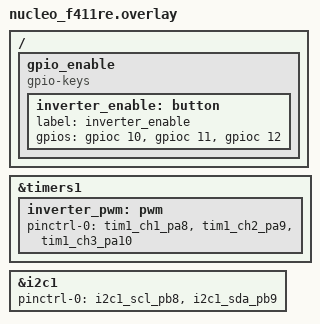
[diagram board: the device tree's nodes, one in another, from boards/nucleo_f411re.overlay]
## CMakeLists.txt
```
cmake_minimum_required(VERSION 3.13.1)
find_package(Zephyr REQUIRED HINTS $ENV{ZEPHYR_BASE})
project(step_foc)

target_sources(app PRIVATE src/foc_driver.c)
target_sources(app PRIVATE src/main.c)
target_sources(app PRIVATE src/foc_nodes.c)
```

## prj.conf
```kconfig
CONFIG_PRINTK=y
CONFIG_SERIAL=y
CONFIG_CBPRINTF_FP_SUPPORT=y

CONFIG_SHELL=y
CONFIG_SHELL_HISTORY=y
CONFIG_SHELL_VT100_COLORS=y

CONFIG_LOG=y
CONFIG_LOG_MODE_DEFERRED=y

CONFIG_STEP=y

# necessary to use CMSIS-DSP
CONFIG_NEWLIB_LIBC=y
CONFIG_CMSIS_DSP=y
CONFIG_CMSIS_DSP_FASTMATH=y
CONFIG_CMSIS_DSP_CONTROLLER=y

# enable PWM
CONFIG_PWM=y

# also the I2C:
CONFIG_I2C=y
```

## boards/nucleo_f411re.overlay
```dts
/*
 * SPDX-License-Identifier: Apache-2.0
 *
 * Copyright (c) 2022 Linaro
 */

 #include <dt-bindings/pwm/pwm.h>

/ {
	gpio_enable {
		compatible = "gpio-keys";
		inverter_enable: button {
			label = "inverter_enable";
			gpios = <&gpioc 10 GPIO_ACTIVE_HIGH>,
                    <&gpioc 11 GPIO_ACTIVE_HIGH>,
                    <&gpioc 12 GPIO_ACTIVE_HIGH>;
		};
	};
};
 
 /* Set PWM that are attached to the IHM07 dev board's power stage */
 &timers1 {
     status = "okay";
 
     inverter_pwm: pwm {
         status = "okay";
         pinctrl-0 = <&tim1_ch1_pa8 &tim1_ch2_pa9 &tim1_ch3_pa10>; 
         pinctrl-names = "default";
     };
};

&i2c1 {
	pinctrl-0 = <&i2c1_scl_pb8 &i2c1_sda_pb9>;
	pinctrl-names = "default";
	status = "okay";
};
```

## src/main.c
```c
/*
 * Copyright (c) 2022 Linaro
 *
 * SPDX-License-Identifier: Apache-2.0
 */

#include <zephyr/kernel.h>
#include <stdlib.h>
#include <step/step.h>
#include <step/proc_mgr.h>
#include <zephyr/shell/shell.h>
#include "foc_driver.h"
#include "foc_nodes.h"

#define SAMPLE_MOTOR_POLE_PAIRS 	7

static float motor_vq;
static float motor_vd;

void on_foc_measurement(struct step_measurement *mes)
{
	/* just update the desired voltage, data publish is handled by
	 * by the driver automatically
	 */
	struct foc_controller_payload *p = mes->payload;
	p->cmd.voltage_q = motor_vq;
	p->cmd.voltage_d = motor_vd;
}

void main(void)
{	
	int rc = 0;
	uint32_t handle;

	motor_vq = 0.0f;
	motor_vd = 0.0f;

	/* initialize the foc driver first */
	rc = foc_driver_initialize(SAMPLE_MOTOR_POLE_PAIRS,
							on_foc_measurement);
	if (rc) {
		printk("foc driver init failed!\n");
		return;
	}

	/* Then register the FoC processing pipeline */
	rc = step_pm_register(foc_node_chain, 0, &handle);
	if (rc) {
		printk("Node registration failed!\n");
		return;
	}
}

static int step_foc_cmd_set(const struct shell *shell, size_t argc, char **argv)
{
	if (argc != 3) {
		return -EINVAL;
	}

	motor_vq = strtof(argv[1], NULL);
	motor_vd = strtof(argv[2], NULL);
	return 0;
}

static int step_foc_cmd_align(const struct shell *shell, size_t argc, char **argv)
{
	return foc_driver_set_encoder_offset();
}

/* Subcommand array for "step_foc" (level 1). */
SHELL_STATIC_SUBCMD_SET_CREATE(
	sub_step_foc,
	SHELL_CMD(set, NULL, "Set voltage d-q vector to control the motor between -1 and +1", step_foc_cmd_set),
	SHELL_CMD(align, NULL, "Align rotor and calibrate its position sensor", step_foc_cmd_align),	
	SHELL_SUBCMD_SET_END
	);

/* Root command "step_foc" (level 0). */
SHELL_CMD_REGISTER(step_foc, &sub_step_foc, "Secure telemetry pipeline FoC sample commands", NULL);
```

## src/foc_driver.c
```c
/*
 * Copyright (c) 2022 Linaro
 *
 * SPDX-License-Identifier: Apache-2.0
 */

#include <arm_math.h>
#include <string.h>
#include <zephyr/kernel.h>
#include <zephyr/device.h>
#include <zephyr/drivers/i2c.h>
#include <zephyr/drivers/pwm.h>
#include <zephyr/drivers/gpio.h>
#include <zephyr/sys/printk.h>
#include <step/sample_pool.h>
#include <step/proc_mgr.h>
#include "foc_driver.h"

/** AS5600 I2C Encoder constants */
#define AS5600_SLAVE_ADDR 0x36
#define AS5600_ANGLE_REGISTER_H 0x0E
#define AS5600_PULSES_PER_REVOLUTION 4096.0f
#define AS5600_READING_MASK 0xFFF 

#define ROTOR_DRV_PAYLOAD_SZ      (sizeof(struct foc_controller_payload))
#define ROTOR_DRV_PAYLOAD_SRC_ID  (2)

/* PWM frequency about 16KHz */
#define PWM_PERIOD_NSEC 62500

/**
 * @brief Pre-populated measurement header to copy into allocated measurements.
 */
static struct step_mes_header rotor_sensor_header = {
	/* Filter word. */
	.filter = {
		.base_type = STEP_MES_TYPE_PHASE,
		.flags = {
			.data_format = STEP_MES_FORMAT_NONE,
			.encoding = STEP_MES_ENCODING_NONE,
			.compression = STEP_MES_COMPRESSION_NONE,
			.timestamp = STEP_MES_TIMESTAMP_UPTIME_MS_32,
		},
	},
	/* SI Unit word. */
	.unit = {
		.si_unit = STEP_MES_UNIT_SI_RADIAN,
		.ctype = STEP_MES_UNIT_CTYPE_IEEE754_FLOAT32,
		.scale_factor = STEP_MES_SI_SCALE_NONE,
	},
	/* Source/Len word. */
	.srclen = {
		.len = ROTOR_DRV_PAYLOAD_SZ,
		.fragment = 0,
		.sourceid = ROTOR_DRV_PAYLOAD_SRC_ID,
	}
};

static void foc_driver_rotor_position_sample_thread(void *arg);

/* Rotor sensor measurement thread. */
K_THREAD_DEFINE(rotor_sample_tid, 4096,
		foc_driver_rotor_position_sample_thread, NULL, NULL, NULL,
		-1, 0, 0);

const static float encoder_to_degrees_ratio = (360.0f) / AS5600_PULSES_PER_REVOLUTION;

static foc_measurement_callback_t user_callback;
static float pole_pairs;

static struct {
	uint16_t raw;
	uint16_t zero_offset;
} encoder_reading;

static const struct device *inverter_pwm = DEVICE_DT_GET(DT_NODELABEL(inverter_pwm));
static const struct device *encoder_i2c = DEVICE_DT_GET(DT_NODELABEL(i2c1));

static struct gpio_dt_spec enable_u = GPIO_DT_SPEC_GET_BY_IDX(DT_NODELABEL(inverter_enable),gpios,0);
static struct gpio_dt_spec enable_v = GPIO_DT_SPEC_GET_BY_IDX(DT_NODELABEL(inverter_enable),gpios,1);
static struct gpio_dt_spec enable_w = GPIO_DT_SPEC_GET_BY_IDX(DT_NODELABEL(inverter_enable),gpios,2);

static uint16_t foc_driver_read_encoder(void)
{
	uint16_t raw;
	uint8_t read_data[2] = {0,0};
	uint8_t angle_reg = AS5600_ANGLE_REGISTER_H;

	/* gets the raw position from encoder */
	int err = i2c_write_read(encoder_i2c, 
						AS5600_SLAVE_ADDR,
						&angle_reg,
						1,
						&read_data,
						sizeof(read_data));

	if(err) {
		return 0xFFFF;
	}

	raw = ((uint16_t)read_data[0] << 8) | read_data[1];

	/* wrap to its maximum value */
	if(raw > AS5600_PULSES_PER_REVOLUTION - 1) {
		raw = AS5600_PULSES_PER_REVOLUTION - 1 ;
	}

	return raw;
}

static void foc_driver_get_rotor_position(struct step_measurement * rotor_measurement)
{
	struct foc_controller_payload *p = rotor_measurement->payload;
	struct foc_feeback_sensor_data *fdbk = &p->state;

	fdbk->motor_pole_pairs = pole_pairs;

	/* update the encoder reading */
	encoder_reading.raw = foc_driver_read_encoder();

	/* make encoder measures to radians for mech and electrical angle */
	fdbk->rotor_position = (float)((encoder_reading.raw - encoder_reading.zero_offset) &
						 AS5600_READING_MASK) * encoder_to_degrees_ratio;
	fdbk->e_rotor_position = fdbk->motor_pole_pairs * fdbk->rotor_position;

	p->timestamp = k_uptime_get_32();
}

static void foc_driver_rotor_position_sample_thread(void *arg)
{	
	for(;;) {
		struct step_measurement *rotor_measurement =  step_sp_alloc(ROTOR_DRV_PAYLOAD_SZ);

		foc_driver_get_rotor_position(rotor_measurement);

		/* fill measurements information before publishing: */
		rotor_measurement->header.filter_bits = rotor_sensor_header.filter_bits;
		rotor_measurement->header.unit_bits = rotor_sensor_header.unit_bits;
		rotor_measurement->header.srclen_bits = rotor_sensor_header.srclen_bits;

		if(user_callback) {
			user_callback(rotor_measurement);
		}

		step_pm_put(rotor_measurement);
	}
}

int foc_driver_initialize(float motor_pole_pairs, foc_measurement_callback_t cb)
{
	int rc = 0;

	user_callback = cb;
	pole_pairs = motor_pole_pairs;

	encoder_reading.raw = 0;
	encoder_reading.zero_offset = 0;

	i2c_configure(encoder_i2c, I2C_MODE_MASTER | I2C_SPEED_FAST);
	foc_driver_set_duty_cycle(0.0f, 0.0f, 0.0f);

	gpio_pin_configure_dt(&enable_u, GPIO_OUTPUT);
	gpio_pin_configure_dt(&enable_v, GPIO_OUTPUT);
	gpio_pin_configure_dt(&enable_w, GPIO_OUTPUT);

	gpio_pin_set_dt(&enable_u, 1);
	gpio_pin_set_dt(&enable_v, 1);
	gpio_pin_set_dt(&enable_w, 1);

	return rc;
}

int foc_driver_set_encoder_offset(void)
{
	/* align rotor each startup */
	encoder_reading.zero_offset = foc_driver_read_encoder() & AS5600_READING_MASK;

	return 0;
}

void foc_driver_set_duty_cycle(float dc_u, float dc_v, float dc_w)
{
	/* saturate the duties */
	if(dc_u > 1.0f) {
		dc_u = 1.0f;
	} else if (dc_u < 0.0f) {
		dc_u = 0.0f;
	}

	if(dc_v > 1.0f) {
		dc_v = 1.0f;
	} else if (dc_v < 0.0f) {
		dc_v = 0.0f;
	}

	if(dc_w > 1.0f) {
		dc_w = 1.0f;
	} else if (dc_w < 0.0f) {
		dc_w = 0.0f;
	}

	/* scale the duty cycle to nanoseconds */
	dc_u *= PWM_PERIOD_NSEC - 1;
	dc_v *= PWM_PERIOD_NSEC - 1;
	dc_w *= PWM_PERIOD_NSEC - 1;

	pwm_set(inverter_pwm, 1 , PWM_PERIOD_NSEC, dc_u, 0);
	pwm_set(inverter_pwm, 2 , PWM_PERIOD_NSEC, dc_v, 0);
	pwm_set(inverter_pwm, 3 , PWM_PERIOD_NSEC, dc_w, 0);
}
```

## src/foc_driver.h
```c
/*
 * Copyright (c) 2022 Linaro
 *
 * SPDX-License-Identifier: Apache-2.0
 */

#ifndef FOC_DRIVER_H__
#define FOC_DRIVER_H__

#include <step/step.h>
#include <step/measurement/measurement.h>

#ifdef __cplusplus
extern "C" {
#endif

/**
 * @brief FoC measurement reception callback:
 */
typedef void (*foc_measurement_callback_t) (struct step_measurement *mes);

/**
 * @brief FoC rotor position sensor data:
 */
struct foc_feeback_sensor_data {
	float motor_pole_pairs;
	float e_rotor_position;
	float rotor_position;
};

/**
 * @brief FoC voltages flow data:
 */
struct foc_command_data {
	float voltage_q;
	float voltage_d;
	float voltage_alpha;
	float voltage_beta;
	float voltage_u;
	float voltage_v;
};

/**
 * @brief FoC data payload descriptor:
 */
struct foc_controller_payload {
	uint32_t timestamp;
	struct foc_feeback_sensor_data state;
	struct foc_command_data cmd;
};

/**
 * @brief Initializes the foc driver.
 * 
 * @param cb user callback to be executed each measurement from motor rotor position.
 * 
 * @param dc_link_voltage inverter dc bus voltage in volts.
 *
 * @param motor_pole_pairs number of motor pole pairs.
 * 
 * @return int  0 on success, otherwise a negative error code.
 * 
 */
int foc_driver_initialize(float motor_pole_pairs, float dc_link_voltage, foc_measurement_callback_t cb);


/**
 * @brief Sets the 0-degree offset for the encoder
 * 
 * @return int  0 on success, otherwise a negative error code.
 * 
 */
int foc_driver_set_encoder_offset(void);

/**
 * @brief set inverter voltages.
 * 
 * @param voltage_u voltage to be applied to the in phase u of motor
 *
 * @param voltage_v voltage to be applied to the in phase v of motor
 * 
 */
void foc_driver_set_voltages(float voltage_u, float voltage_v);

#ifdef __cplusplus
}
#endif

#endif /* STEP_SHELL_DRIVER_H_ */
```

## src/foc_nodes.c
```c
/*
 * Copyright (c) 2022 Linaro
 *
 * SPDX-License-Identifier: Apache-2.0
 */

#include <zephyr/kernel.h>
#include <stdio.h>
#include <zephyr/logging/log.h>
#include <step/proc_mgr.h>
#include "foc_nodes.h"
#include "foc_driver.h"
#include "foc_svm.h"
#include <arm_math.h>

/**
 *  ┌───────────────┐
 *  │               │
 *  │ Rotor Sensor  │          This is the FoC pipeline created using STeP:
 *  │ (I2C)         │       1. Collect node which is trigggered by rotor position sensor driver
 *  │               │       2. Inverse Park transfor to map VQD to rotating VaplhaBeta
 *  │               │       3. Inverse Clarke transform to project ValphaBeta into 3-phase vector
 *  └──────┬────────┘       4. Inverter update node that sends 3-phase vector to the PWM driver
 *         │
 *         │                The STeP node chain is created to represent the block diagram
 *         │                below.
 *         │
 *         │
 *         │           ---------------------------------------------------
 *         │		   | FoC algorithm Node								 |						 	
 * ┌───────▼────────┐  | ┌────────────────┐            ┌───────────────┐ |       ┌────────────────┐
 * │                │  | │                │            │               │ |       │                │
 * │  Collect       │  | │ Inverse        │            │ Inverse       │ |       │ Inverter       │
 * │  Node          │  | │ Park Transform │            │ Clarke Trans. │ |       │ Update         │
 * │                ├───►│                ├────────────►               ├────────►│ Node           │
 * │  Capture       │  | │ VQD -> Vab     │            │ Vab->Vuvw     │ |       │ Vuvw-> SVPWM   │
 * │  the samples   │  | │                │            │               │ |       │                │
 * │                │  | │                │            │               │ |       │                │
 * └───────▲────────┘  | └────────────────┘            └───────────────┘ |       └────────┬───────┘
 *         │           |                                                 |                │
 *         │           |-------------------------------------------------|                │
 *         │                                                                              ▼
 *         │                                                                     ┌────────────────┐
 *  ┌──────┴────────┐                                                            │                │
 *  │               │                                                            │ Inverter       │
 *  │ Desired       │                                                            │ Driver         │
 *  │ Voltage       │                                                            │                │
 *  │ (Shell)       │                                                            │ (PWM)          │
 *  │               │                                                            │                │
 *  │               │                                                            └────────────────┘
 *  └───────────────┘
 */

/* rotor sensor align step */
int foc_align_rotor(void *cfg, uint32_t handle, uint32_t inst)
{
	/* for rotor alignment the idea is to provide the initial voltage
	 * vector with a phase of 90 degree and apply to the motor, and wait
	 * the rotor to align mechanically to that voltage applied, this will
	 * translate the stator and rotor magnetic fields are properly 90 degree
	 * aligned
	 */
	float sine;
	float cosine;
	float alpha;
	float beta;
	float inverter_duties[3];

	/* we want a voltage vector with 90 degree of phase */
	arm_sin_cos_f32(90, &sine, &cosine);

	/* use only 20% of the current capacity to avoid heating*/
	arm_inv_park_f32(0.0f,
					0.1f,
					&alpha,
					&beta,
					sine,
					cosine);

	/* convert the alpha-beta frame into SVPWM signals */
	foc_svm_set(alpha, 
			beta,
			&inverter_duties[0],
			&inverter_duties[1],
			&inverter_duties[2]);

	/* set the voltage vector to the inverter and... */
	foc_driver_set_duty_cycle(inverter_duties[0], inverter_duties[1], inverter_duties[2]);
	
	/* give a delay to the rotor align mechanically */
	k_sleep(K_MSEC(500));

	/* before releasing the voltage, sets the zero angle offset in the encoder*/
	return foc_driver_set_encoder_offset();
}

/* foc algorithm process step */
int foc_do_process(struct step_measurement *mes, uint32_t handle, uint32_t inst)
{
	struct foc_controller_payload *p = mes->payload;
	struct foc_command_data *command = &p->cmd;
	struct foc_feeback_sensor_data *feed = &p->state;
	float sine;
	float cosine;

	arm_sin_cos_f32(feed->e_rotor_position, &sine, &cosine);

	arm_inv_park_f32(command->voltage_d,
					command->voltage_q,
					&command->voltage_alpha,
					&command->voltage_beta,
					sine,
					cosine);
	
	return 0;
}

/* do SVPWM update the inverter step, the last block on FoC chain */
int foc_do_space_vector_modulation(struct step_measurement *mes, uint32_t handle, uint32_t inst)
{
	struct foc_controller_payload *p = mes->payload;
	float inverter_duties[3];

	/* convert the alpha-beta frame into SVPWM signals */
	foc_svm_set(p->cmd.voltage_alpha, 
			p->cmd.voltage_beta,
			&inverter_duties[0],
			&inverter_duties[1],
			&inverter_duties[2]);

	/* and transfer them directly to the inverter */
	foc_driver_set_duty_cycle(inverter_duties[0], inverter_duties[1], inverter_duties[2]);
	
	return 0;
}

/* Processor node chain. */
struct step_node foc_node_chain_data[] = {
	/* Root processor node. */
	{
		.name = "Root sensor sample processor node",
		.filters = {
			.count = 1,
			.chain = (struct step_filter[]){
				{
					/* Phase (base type). */
					.match = STEP_MES_TYPE_PHASE,
					.ignore_mask = ~STEP_MES_MASK_FULL_TYPE,
				}
			},
		},

		/* Callbacks */
		.callbacks = {
			.init_handler = foc_align_rotor,
		},

		/* Config settings */
		.config = NULL,

		/* Point to next processor node in chain. */
		.next = &foc_node_chain_data[1]
	},

	/* Processor node 1. */
	{
		.name = "foc processing node",
		/* Callbacks */
		.callbacks = {
			.exec_handler = foc_do_process,
		},

		/* Config settings */
		.config = NULL,

		/* Point to next processor node in chain. */
		.next = &foc_node_chain_data[2]
	},

	/* Processor node 2. */
	{
		.name = "inverter update",
		/* Callbacks */
		.callbacks = {
			.exec_handler = foc_do_space_vector_modulation,
		},

		/* Config settings */
		.config = NULL,

		/* End of the chain. */
		.next = NULL
	},
};

/* Pointer to node chain. */
struct step_node *foc_node_chain = foc_node_chain_data;
```

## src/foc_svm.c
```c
/*
 * Copyright (c) 2021 Teslabs Engineering S.L.
 * Copyright (c) 2022 Linaro 
 * SPDX-License-Identifier: Apache-2.0
 */

#include <sys/util.h>
#include <arm_math.h>
#include "foc_svm.h"

/** Value sqrt(3). */
#define SQRT_3 1.7320508075688773f
static const float sqrt3_by_two = SQRT_3 / 2.0f;

/**
 * @brief Obtain sector based on a, b, c vector values.
 *
 * @param[in] a a component value.
 * @param[in] b b component value.
 * @param[in] c c component value.

 * @return Sector (1...6).
 */
static uint8_t get_sector(float a, float b, float c)
{
	uint8_t sector = 0U;

	if (c < 0.0f) {
		if (a < 0.0f) {
			sector = 2U;
		} else {
			if (b < 0.0f) {
				sector = 6U;
			} else {
				sector = 1U;
			}
		}
	} else {
		if (a < 0.0f) {
			if (b <= 0.0f) {
				sector = 4U;
			} else {
				sector = 3U;
			}
		} else {
			sector = 5U;
		}
	}

	return sector;
}

void foc_svm_set(float v_alpha, float v_beta, float *dca, float *dcb, float *dcc)
{
	float a, b, c, mod;
	float x, y, z;

	/* normalize and limit alpha-beta vector */
	(void)arm_sqrt_f32(v_alpha * v_alpha + v_beta * v_beta, &mod);
	if (mod > sqrt3_by_two) {
		v_alpha = v_alpha / mod * sqrt3_by_two;
		v_beta = v_beta / mod * sqrt3_by_two;
	}

	/* do a modified inverse clarke transform to get an auxiliary frame 
	 * to compute the sector we are
	 */
	a = v_alpha;
	b = 0.5f * (-v_alpha - SQRT_3 * v_beta);
	c = 0.5f * (-v_alpha + SQRT_3 * v_beta); 

	switch (get_sector(a, b, c)) {
	case 1U:
		x = a;
		y = b;
		z = 1.0f - (x + y);

		*dca = x + y + z * 0.5f;
		*dcb = y + z * 0.5f;
		*dcc = z * 0.5f;

		break;
	case 2U:
		x = -c;
		y = -a;
		z = 1.0f - (x + y);

		*dca = x + z * 0.5f;
		*dcb = x + y + z * 0.5f;
		*dcc = z * 0.5f;

		break;
	case 3U:
		x = b;
		y = c;
		z = 1.0f - (x + y);

		*dca = z * 0.5f;
		*dcb = x + y + z * 0.5f;
		*dcc = y + z * 0.5f;

		break;
	case 4U:
		x = -a;
		y = -b;
		z = 1.0f - (x + y);

		*dca = z * 0.5f;
		*dcb = x + z * 0.5f;
		*dcc = x + y + z * 0.5f;

		break;
	case 5U:
		x = c;
		y = a;
		z = 1.0f - (x + y);

		*dca = y + z * 0.5f;
		*dcb = z * 0.5f;
		*dcc = x + y + z * 0.5f;

		break;
	case 6U:
		x = -b;
		y = -c;
		z = 1.0f - (x + y);

		*dca = x + y + z * 0.5f;
		*dcb = z * 0.5f;
		*dcc = x + z * 0.5f;

		break;
	default:
		break;
	}
}
```
